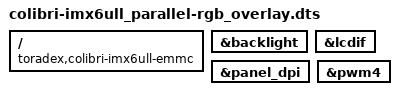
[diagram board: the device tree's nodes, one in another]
// SPDX-License-Identifier: GPL-2.0-or-later OR MIT
/*
 * Copyright 2021 Toradex
 */

// Enable the parallel RGB interface on the Colibri iMX6ULL. Make sure to also
// select a valid display configuration.

/dts-v1/;
/plugin/;

/ {
	compatible = "toradex,colibri-imx6ull-emmc";
};

&backlight {
	status = "okay";
};

&lcdif {
	status = "okay";
};

&panel_dpi {
	status = "okay";
};

&pwm4 {
	status = "okay";
};
